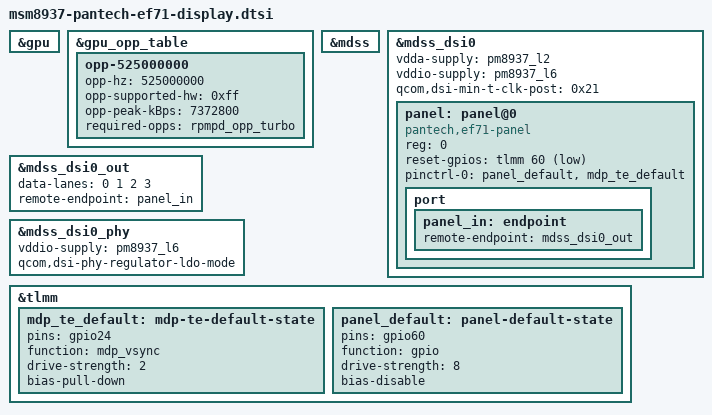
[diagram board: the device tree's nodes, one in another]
// SPDX-License-Identifier: GPL-2.0-only
/*
 * EF71 GPU and display: Adreno 505, MDSS and the panel on DSI0, the
 * NT35695 command mode panel of the EF71S or the FT8716 video mode panel of
 * the EF71AS.
 *
 * Copyright (c) 2026, hiru <rlawoehd187@naver.com>
 */

#include <dt-bindings/gpio/gpio.h>

&gpu {
	status = "okay";
};

/*
 * No 19.2 MHz level, as on the stock kernel (216 MHz the lowest): from
 * there simple_ondemand takes frames of polling to bring the GPU up.
 */
&gpu_opp_table {
	/delete-node/ opp-19200000;

	/*
	 * Above the 450 MHz of the stock kernel, at the same voltage: until
	 * GPLL3 got its post divider this was what 450 MHz ran at, through
	 * all of the Vulkan conformance runs.
	 */
	opp-525000000 {
		opp-hz = /bits/ 64 <525000000>;
		opp-supported-hw = <0xff>;
		/* the top of the stock GPU bus table */
		opp-peak-kBps = <7372800>;
		required-opps = <&rpmpd_opp_turbo>;
	};
};

&mdss {
	status = "okay";
};

&mdss_dsi0 {
	vdda-supply = <&pm8937_l2>;
	vddio-supply = <&pm8937_l6>;

	/*
	 * The vendor T_CLK_POST: at the computed minimum the NT35695 drops
	 * the last lines of every frame and shows noise along the bottom.
	 */
	qcom,dsi-min-t-clk-post = <0x21>;

	status = "okay";

	/*
	 * NT35695 (EF71S) or FT8716 (EF71AS): the panel driver takes the one
	 * the bootloader names in mdss_mdp.panel
	 */
	panel: panel@0 {
		compatible = "pantech,ef71-panel";
		reg = <0>;

		reset-gpios = <&tlmm 60 GPIO_ACTIVE_LOW>;

		pinctrl-0 = <&panel_default &mdp_te_default>;
		pinctrl-names = "default";

		port {
			panel_in: endpoint {
				remote-endpoint = <&mdss_dsi0_out>;
			};
		};
	};
};

&mdss_dsi0_out {
	data-lanes = <0 1 2 3>;
	remote-endpoint = <&panel_in>;
};

&mdss_dsi0_phy {
	vddio-supply = <&pm8937_l6>;
	qcom,dsi-phy-regulator-ldo-mode;

	status = "okay";
};

&tlmm {
	mdp_te_default: mdp-te-default-state {
		pins = "gpio24";
		function = "mdp_vsync";
		drive-strength = <2>;
		bias-pull-down;
	};

	panel_default: panel-default-state {
		pins = "gpio60";
		function = "gpio";
		drive-strength = <8>;
		bias-disable;
	};
};
